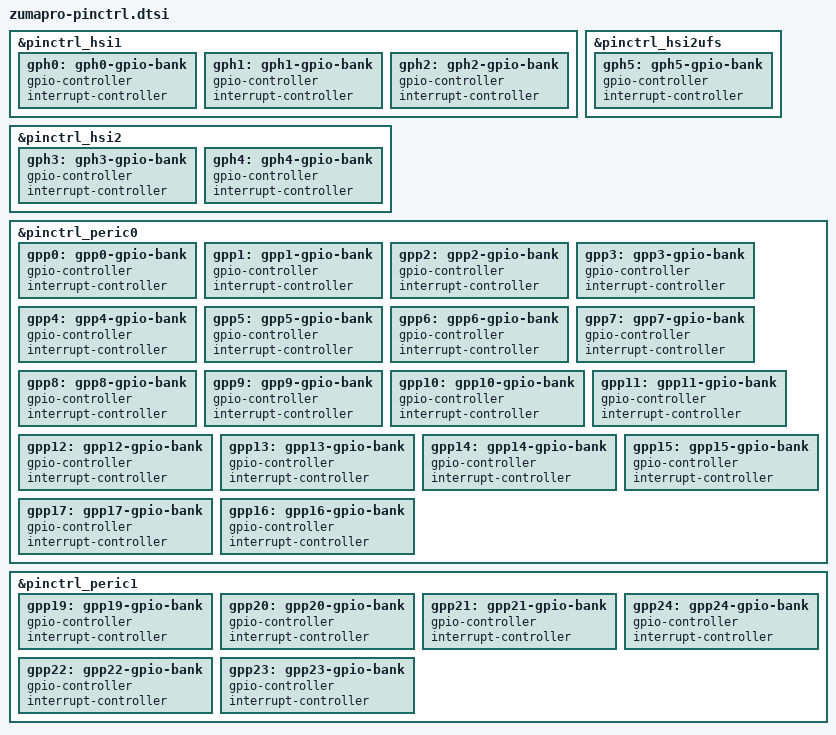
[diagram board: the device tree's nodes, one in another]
// SPDX-License-Identifier: GPL-2.0-only
/*
 * Google Tensor G4 (zumapro) pin-controller GPIO banks
 *
 * Copyright 2026 Will
 */

&pinctrl_hsi1 {
	gph0: gph0-gpio-bank {
		gpio-controller;
		#gpio-cells = <2>;
		interrupt-controller;
		#interrupt-cells = <2>;
	};

	gph1: gph1-gpio-bank {
		gpio-controller;
		#gpio-cells = <2>;
		interrupt-controller;
		#interrupt-cells = <2>;
	};

	gph2: gph2-gpio-bank {
		gpio-controller;
		#gpio-cells = <2>;
		interrupt-controller;
		#interrupt-cells = <2>;
	};
};

&pinctrl_hsi2 {
	gph3: gph3-gpio-bank {
		gpio-controller;
		#gpio-cells = <2>;
		interrupt-controller;
		#interrupt-cells = <2>;
	};

	gph4: gph4-gpio-bank {
		gpio-controller;
		#gpio-cells = <2>;
		interrupt-controller;
		#interrupt-cells = <2>;
	};
};

&pinctrl_hsi2ufs {
	gph5: gph5-gpio-bank {
		gpio-controller;
		#gpio-cells = <2>;
		interrupt-controller;
		#interrupt-cells = <2>;
	};
};

&pinctrl_peric0 {
	gpp0: gpp0-gpio-bank {
		gpio-controller;
		#gpio-cells = <2>;
		interrupt-controller;
		#interrupt-cells = <2>;
	};

	gpp1: gpp1-gpio-bank {
		gpio-controller;
		#gpio-cells = <2>;
		interrupt-controller;
		#interrupt-cells = <2>;
	};

	gpp2: gpp2-gpio-bank {
		gpio-controller;
		#gpio-cells = <2>;
		interrupt-controller;
		#interrupt-cells = <2>;
	};

	gpp3: gpp3-gpio-bank {
		gpio-controller;
		#gpio-cells = <2>;
		interrupt-controller;
		#interrupt-cells = <2>;
	};

	gpp4: gpp4-gpio-bank {
		gpio-controller;
		#gpio-cells = <2>;
		interrupt-controller;
		#interrupt-cells = <2>;
	};

	gpp5: gpp5-gpio-bank {
		gpio-controller;
		#gpio-cells = <2>;
		interrupt-controller;
		#interrupt-cells = <2>;
	};

	gpp6: gpp6-gpio-bank {
		gpio-controller;
		#gpio-cells = <2>;
		interrupt-controller;
		#interrupt-cells = <2>;
	};

	gpp7: gpp7-gpio-bank {
		gpio-controller;
		#gpio-cells = <2>;
		interrupt-controller;
		#interrupt-cells = <2>;
	};

	gpp8: gpp8-gpio-bank {
		gpio-controller;
		#gpio-cells = <2>;
		interrupt-controller;
		#interrupt-cells = <2>;
	};

	gpp9: gpp9-gpio-bank {
		gpio-controller;
		#gpio-cells = <2>;
		interrupt-controller;
		#interrupt-cells = <2>;
	};

	gpp10: gpp10-gpio-bank {
		gpio-controller;
		#gpio-cells = <2>;
		interrupt-controller;
		#interrupt-cells = <2>;
	};

	gpp11: gpp11-gpio-bank {
		gpio-controller;
		#gpio-cells = <2>;
		interrupt-controller;
		#interrupt-cells = <2>;
	};

	gpp12: gpp12-gpio-bank {
		gpio-controller;
		#gpio-cells = <2>;
		interrupt-controller;
		#interrupt-cells = <2>;
	};

	gpp13: gpp13-gpio-bank {
		gpio-controller;
		#gpio-cells = <2>;
		interrupt-controller;
		#interrupt-cells = <2>;
	};

	gpp14: gpp14-gpio-bank {
		gpio-controller;
		#gpio-cells = <2>;
		interrupt-controller;
		#interrupt-cells = <2>;
	};

	gpp15: gpp15-gpio-bank {
		gpio-controller;
		#gpio-cells = <2>;
		interrupt-controller;
		#interrupt-cells = <2>;
	};

	gpp17: gpp17-gpio-bank {
		gpio-controller;
		#gpio-cells = <2>;
		interrupt-controller;
		#interrupt-cells = <2>;
	};

	gpp16: gpp16-gpio-bank {
		gpio-controller;
		#gpio-cells = <2>;
		interrupt-controller;
		#interrupt-cells = <2>;
	};
};

&pinctrl_peric1 {
	gpp19: gpp19-gpio-bank {
		gpio-controller;
		#gpio-cells = <2>;
		interrupt-controller;
		#interrupt-cells = <2>;
	};

	gpp20: gpp20-gpio-bank {
		gpio-controller;
		#gpio-cells = <2>;
		interrupt-controller;
		#interrupt-cells = <2>;
	};

	gpp21: gpp21-gpio-bank {
		gpio-controller;
		#gpio-cells = <2>;
		interrupt-controller;
		#interrupt-cells = <2>;
	};

	gpp24: gpp24-gpio-bank {
		gpio-controller;
		#gpio-cells = <2>;
		interrupt-controller;
		#interrupt-cells = <2>;
	};

	gpp22: gpp22-gpio-bank {
		gpio-controller;
		#gpio-cells = <2>;
		interrupt-controller;
		#interrupt-cells = <2>;
	};

	gpp23: gpp23-gpio-bank {
		gpio-controller;
		#gpio-cells = <2>;
		interrupt-controller;
		#interrupt-cells = <2>;
	};
};
